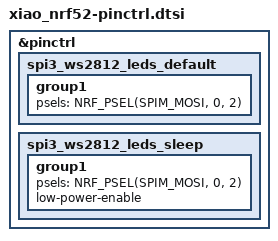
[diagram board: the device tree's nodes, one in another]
/*
 * SPDX-FileCopyrightText: Copyright (c) 2026 TiaC Systems
 * SPDX-License-Identifier: Apache-2.0
 */

&pinctrl {
	spi3_ws2812_leds_default: spi3_ws2812_leds_default {
		group1 {
			psels = <NRF_PSEL(SPIM_MOSI, 0, 2)>;	/* SPI3:COPI @ XIAO_D0(P0.02) */
		};
	};

	spi3_ws2812_leds_sleep: spi3_ws2812_leds_sleep {
		group1 {
			psels = <NRF_PSEL(SPIM_MOSI, 0, 2)>;	/* SPI3:COPI @ XIAO_D0(P0.02) */
			low-power-enable;
		};
	};
};
